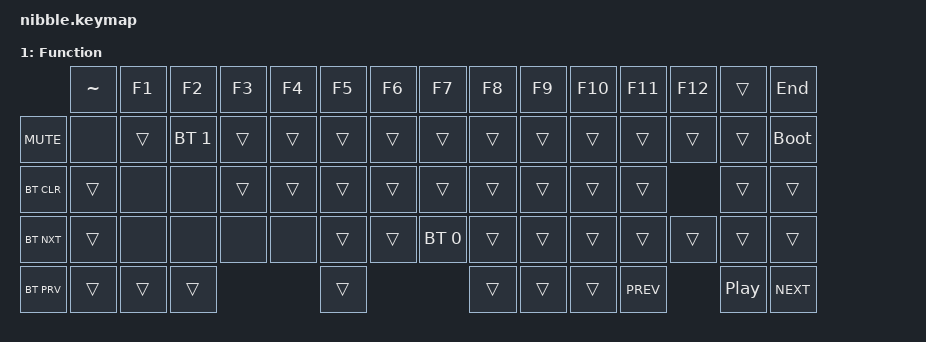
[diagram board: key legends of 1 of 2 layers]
/*
 * Copyright (c) 2020 The ZMK Contributors
 *
 * SPDX-License-Identifier: MIT
 */

#include <behaviors.dtsi>
#include <dt-bindings/zmk/bt.h>
#include <dt-bindings/zmk/keys.h>

/ {
    sensors {
        compatible = "zmk,keymap-sensors";
        sensors = <&encoder_1>;
    };

    keymap {
        compatible = "zmk,keymap";

        default_layer {
            label = "Default";
            sensor-bindings = <&inc_dec_kp C_VOLUME_DOWN C_VOLUME_UP>;
            bindings = <
                  &kp GRAVE  &kp N1        &kp N2        &kp N3  &kp N4  &kp N5     &kp N6  &kp N7  &kp N8  &kp N9     &kp N0     &kp MINUS  &kp EQUAL  &kp BSPC  &kp ESC
&kp C_MUTE        &kp TAB    &kp Q         &kp W         &kp E   &kp R   &kp T      &kp Y   &kp U   &kp I   &kp O      &kp P      &kp LBKT   &kp RBKT   &kp BSLH  &kp DEL
&kp C_PLAY_PAUSE  &kp CAPS   &kp A         &kp S         &kp D   &kp F   &kp G      &kp H   &kp J   &kp K   &kp L      &kp SEMI   &kp SQT               &kp RET   &kp PG_UP
&kp K_POWER       &kp LSHFT  &kp Z         &kp X         &kp C   &kp V   &kp B      &kp N           &kp M   &kp COMMA  &kp DOT    &kp FSLH   &kp RSHFT  &kp UP    &kp PG_DN
&sys_reset        &kp LCTRL  &kp LEFT_WIN  &kp LEFT_ALT                  &kp SPACE                  &mo 1   &kp RALT   &kp RCTRL  &kp LEFT              &kp DOWN  &kp RIGHT
            >;
        };

        function_layer {
            label = "Function";
            sensor-bindings = <&inc_dec_kp C_VOLUME_DOWN C_VOLUME_UP>;
            bindings = <
            &kp TILDE  &kp F1  &kp F2        &kp F3  &kp F4  &kp F5  &kp F6  &kp F7        &kp F8  &kp F9  &kp F10  &kp F11     &kp F12  &trans    &kp END
&kp C_MUTE  &none      &trans  &bt BT_SEL 1  &trans  &trans  &trans  &trans  &trans        &trans  &trans  &trans   &trans      &trans   &trans    &bootloader
&bt BT_CLR  &trans     &none   &none         &trans  &trans  &trans  &trans  &trans        &trans  &trans  &trans   &trans               &trans    &trans
&bt BT_NXT  &trans     &none   &none         &none   &none   &trans  &trans  &bt BT_SEL 0  &trans  &trans  &trans   &trans      &trans   &trans    &trans
&bt BT_PRV  &trans     &trans  &trans                        &trans                        &trans  &trans  &trans   &kp C_PREV           &kp C_PP  &kp C_NEXT
            >;
        };
    };
};
